AUTOSAR XML (schema 00046)
package /ComponentTypes
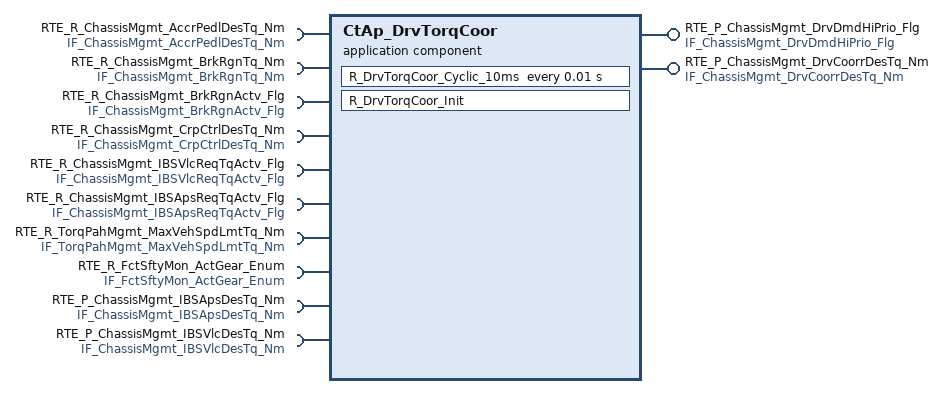
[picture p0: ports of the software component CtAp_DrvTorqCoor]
  application sw component type CtAp_DrvTorqCoor
    8 x require port:
      RTE_R_ChassisMgmt_AccrPedlDesTq_Nm: nonqueued-receiver-com-spec{data-element=tec_ChassisMgmt_AccrPedlDesTq_Nm, filter=data-filter-type=ALWAYS, init-value=0}, required-interface=IF_ChassisMgmt_AccrPedlDesTq_Nm
      RTE_R_ChassisMgmt_BrkRgnTq_Nm: nonqueued-receiver-com-spec{data-element=tec_ChassisMgmt_BrkRgnTq_Nm, filter=data-filter-type=ALWAYS, init-value=0}, required-interface=IF_ChassisMgmt_BrkRgnTq_Nm
      RTE_R_ChassisMgmt_BrkRgnActv_Flg: nonqueued-receiver-com-spec{data-element=tec_ChassisMgmt_BrkRgnActv_Flg, filter=data-filter-type=ALWAYS, init-value=0}, required-interface=IF_ChassisMgmt_BrkRgnActv_Flg
      RTE_R_ChassisMgmt_CrpCtrlDesTq_Nm: nonqueued-receiver-com-spec{data-element=tec_ChassisMgmt_CrpCtrlDesTq_Nm, filter=data-filter-type=ALWAYS, init-value=0}, required-interface=IF_ChassisMgmt_CrpCtrlDesTq_Nm
      RTE_R_ChassisMgmt_IBSVlcReqTqActv_Flg: nonqueued-receiver-com-spec{data-element=tec_ChassisMgmt_IBSVlcReqTqActv_Flg, filter=data-filter-type=ALWAYS, init-value=0}, required-interface=IF_ChassisMgmt_IBSVlcReqTqActv_Flg
      RTE_R_ChassisMgmt_IBSApsReqTqActv_Flg: nonqueued-receiver-com-spec{data-element=tec_ChassisMgmt_IBSApsReqTqActv_Flg, filter=data-filter-type=ALWAYS, init-value=0}, required-interface=IF_ChassisMgmt_IBSApsReqTqActv_Flg
      RTE_R_TorqPahMgmt_MaxVehSpdLmtTq_Nm: nonqueued-receiver-com-spec{data-element=tec_TorqPahMgmt_MaxVehSpdLmtTq_Nm, filter=data-filter-type=ALWAYS, init-value=0}, required-interface=IF_TorqPahMgmt_MaxVehSpdLmtTq_Nm
      RTE_R_FctSftyMon_ActGear_Enum: nonqueued-receiver-com-spec{data-element=tec_FctSftyMon_ActGear_Enum, filter=data-filter-type=ALWAYS, init-value=0}, required-interface=IF_FctSftyMon_ActGear_Enum
    provide port RTE_P_ChassisMgmt_DrvDmdHiPrio_Flg: nonqueued-sender-com-spec{data-element=tec_ChassisMgmt_DrvDmdHiPrio_Flg, init-value=0}, provided-interface=IF_ChassisMgmt_DrvDmdHiPrio_Flg
    provide port RTE_P_ChassisMgmt_DrvCoorrDesTq_Nm: nonqueued-sender-com-spec{data-element=tec_ChassisMgmt_DrvCoorrDesTq_Nm, init-value=0}, provided-interface=IF_ChassisMgmt_DrvCoorrDesTq_Nm
    require port RTE_P_ChassisMgmt_IBSApsDesTq_Nm: nonqueued-receiver-com-spec{data-element=tec_ChassisMgmt_IBSApsDesTq_Nm, filter=data-filter-type=ALWAYS, init-value=0}, required-interface=IF_ChassisMgmt_IBSApsDesTq_Nm
    require port RTE_P_ChassisMgmt_IBSVlcDesTq_Nm: nonqueued-receiver-com-spec{data-element=tec_ChassisMgmt_IBSVlcDesTq_Nm, filter=data-filter-type=ALWAYS, init-value=0}, required-interface=IF_ChassisMgmt_IBSVlcDesTq_Nm
    behavior CtAp_DrvTorqCoor_InternalBehavior
      timing event TMT_R_DrvTorqCoor_Cyclic_10ms: start-on-event=R_DrvTorqCoor_Cyclic_10ms, period=0.01
      init event CtAp_DrvTorqCoor_InitEvent: start-on-event=R_DrvTorqCoor_Init
      runnable R_DrvTorqCoor_Cyclic_10ms
        data-receive-point-by-arguments:
          10 x access:
            REC_RTE_R_ChassisMgmt_AccrPedlDesTq_Nm_tec_ChassisMgmt_AccrPedlDesTq_Nm: accessed-variable=RTE_R_ChassisMgmt_AccrPedlDesTq_Nm.tec_ChassisMgmt_AccrPedlDesTq_Nm
            REC_RTE_R_ChassisMgmt_BrkRgnActv_Flg_tec_ChassisMgmt_BrkRgnActv_Flg: accessed-variable=RTE_R_ChassisMgmt_BrkRgnActv_Flg.tec_ChassisMgmt_BrkRgnActv_Flg
            REC_RTE_R_ChassisMgmt_BrkRgnTq_Nm_tec_ChassisMgmt_BrkRgnTq_Nm: accessed-variable=RTE_R_ChassisMgmt_BrkRgnTq_Nm.tec_ChassisMgmt_BrkRgnTq_Nm
            REC_RTE_R_ChassisMgmt_CrpCtrlDesTq_Nm_tec_ChassisMgmt_CrpCtrlDesTq_Nm: accessed-variable=RTE_R_ChassisMgmt_CrpCtrlDesTq_Nm.tec_ChassisMgmt_CrpCtrlDesTq_Nm
            REC_RTE_R_ChassisMgmt_IBSApsReqTqActv_Flg_tec_ChassisMgmt_IBSApsReqTqActv_Flg: accessed-variable=RTE_R_ChassisMgmt_IBSApsReqTqActv_Flg.tec_ChassisMgmt_IBSApsReqTqActv_Flg
            REC_RTE_R_ChassisMgmt_IBSVlcReqTqActv_Flg_tec_ChassisMgmt_IBSVlcReqTqActv_Flg: accessed-variable=RTE_R_ChassisMgmt_IBSVlcReqTqActv_Flg.tec_ChassisMgmt_IBSVlcReqTqActv_Flg
            REC_RTE_R_FctSftyMon_ActGear_Enum_tec_FctSftyMon_ActGear_Enum: accessed-variable=RTE_R_FctSftyMon_ActGear_Enum.tec_FctSftyMon_ActGear_Enum
            REC_RTE_R_TorqPahMgmt_MaxVehSpdLmtTq_Nm_tec_TorqPahMgmt_MaxVehSpdLmtTq_Nm: accessed-variable=RTE_R_TorqPahMgmt_MaxVehSpdLmtTq_Nm.tec_TorqPahMgmt_MaxVehSpdLmtTq_Nm
            REC_RTE_P_ChassisMgmt_IBSApsDesTq_Nm_tec_ChassisMgmt_IBSApsDesTq_Nm: accessed-variable=RTE_P_ChassisMgmt_IBSApsDesTq_Nm.tec_ChassisMgmt_IBSApsDesTq_Nm
            REC_RTE_P_ChassisMgmt_IBSVlcDesTq_Nm_tec_ChassisMgmt_IBSVlcDesTq_Nm: accessed-variable=RTE_P_ChassisMgmt_IBSVlcDesTq_Nm.tec_ChassisMgmt_IBSVlcDesTq_Nm
        data-send-points:
          access SEND_RTE_P_ChassisMgmt_DrvDmdHiPrio_Flg_tec_ChassisMgmt_DrvDmdHiPrio_Flg: accessed-variable=RTE_P_ChassisMgmt_DrvDmdHiPrio_Flg.tec_ChassisMgmt_DrvDmdHiPrio_Flg
          access SEND_RTE_P_ChassisMgmt_DrvCoorrDesTq_Nm_tec_ChassisMgmt_DrvCoorrDesTq_Nm: accessed-variable=RTE_P_ChassisMgmt_DrvCoorrDesTq_Nm.tec_ChassisMgmt_DrvCoorrDesTq_Nm
      runnable R_DrvTorqCoor_Init
  swc implementation CtAp_DrvTorqCoor_Implementation: behavior=CtAp_DrvTorqCoor_InternalBehavior
